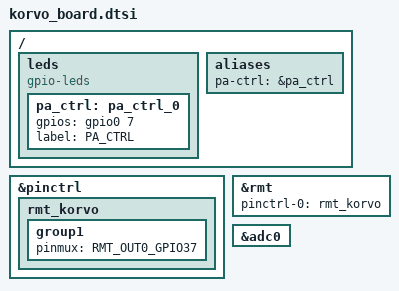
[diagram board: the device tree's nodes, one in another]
/*
 * korvo_board.dtsi —— Korvo-1 与上游 coreboard 之间的"公共差异"
 *
 * 上游板级（zephyr\boards\espressif\esp32s31_function_coreboard）描述的是
 * 乐鑫那块 coreboard；Korvo-1 有三处物理接线不一样，而这三个实验台都要用：
 *
 *   1. 功放使能 PA_CTRL = GPIO7，上游板没有这个节点
 *   2. WS2812 接在 GPIO37，走 RMT OUT0（上游板用的是默认 rmt 引脚）
 *   3. 四个功能键挂在 IO42 的电阻梯上，必须打开 adc0 才能量
 *
 * 用法（各工程的 boards\<板目标>.overlay 里一行）：
 *   #include "../../common/korvo_board.dtsi"
 * （相对路径相对"overlay 文件所在目录"，overlay 在 boards\ 下，所以退两级）
 *
 * 只放"三个以上工程共同成立"的部分；每个工程独有的节点留在自己的 overlay，
 * 否则会把"某工程才需要的外设"强行塞进别的工程（镜像变大、日志变吵）。
 */

/ {
	leds {
		compatible = "gpio-leds";

		pa_ctrl: pa_ctrl_0 {
			gpios = <&gpio0 7 GPIO_ACTIVE_HIGH>;
			label = "PA_CTRL";
		};
	};

	aliases {
		pa-ctrl = &pa_ctrl;
	};
};

/* WS2812：GPIO37 ← RMT OUT0（上游板级里 rmt 已 okay，这里只换输出脚） */
&pinctrl {
	rmt_korvo: rmt_korvo {
		group1 {
			pinmux = <RMT_OUT0_GPIO37>;
		};
	};
};

&rmt {
	pinctrl-0 = <&rmt_korvo>;
	pinctrl-names = "default";
	status = "okay";
};

/* IO42 上的四键是"一路 ADC 读四种电压"，不打开 adc0 就量不到 */
&adc0 {
	status = "okay";
};
